# V32F20x_CM33 register map
File version: 1.0.3
CPU: CM33 r0p4, little endian, MPU, FPU, DSP, 3 interrupt priority bits, 8 SAU regions
Registers are 32-bit, read-write, reset 0x0 unless marked. A register's access mark holds for its fields unless they carry their own. Offsets are from the block's base; [hi:lo] are bit positions; {n}, {i} and the like mark numbered series.

## CRC — CRC Peripheral Interface
Base 0x20300000
Same registers: SEC_CRC 0x30300000
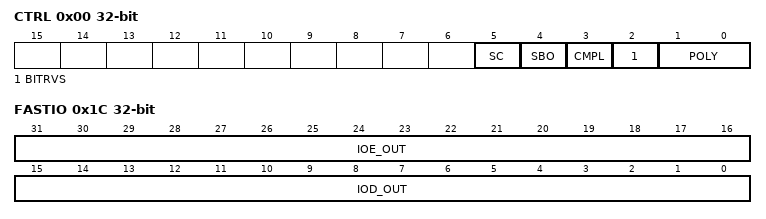
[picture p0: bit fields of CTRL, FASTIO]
0x00 CTRL — Control register.
  [5] SC — CRC sum complement
  [4] SBO — CRC sum bit order
  [3] CMPL — Data complement
  [2] BITRVS — Data bit order
  [1:0] POLY — CRC polynomial:
0x04 SEED wo reset 0xFFFF
  [31:0] SEED — A write access to this register will load CRC seed value to SUM register with select bit order and 1 s complement pre processes
0x08 SUM ro reset 0xFFFF
  [31:0] SUM — The most recent CRC sum can be read through this register with selected bit order and 1 s complement post processes
0x0C DATA wo
  [31:0] DATA — Data written to this register will be taken to perform CRC calculation with selected bit order and 1 s complement pre process
0x10 STATUS ro
  [0] BUSY — When assert to 1 it means the CRC Engine is busy on processing CRC command
0x1C FASTIO — Fast GPIO output data register.
  [31:16] IOE_OUT — The fast GPIOE output data.
  [15:0] IOD_OUT — The fast GPIOD output data.

## UART0 — UART0 Peripheral Interface
Base 0x40010000
Same registers: UART{n} {0x40010000+0x800*n} (n=1..13), UART14 0x41030000, UART15 0x41030800, UART16 0x41031000, UART17 0x41031800, UART18 0x41032000, UART19 0x41032800, SEC_UART{n} {0x50010000+0x800*n} (n=0..13)
0x00 RBR ro — Receive buffer register.
  [7:0] RBR — This register contains the data byte received on the serial input port sin in UART mode If in non FIFO mode the data in the RBR must be read before the next data arrives otherwise it will be overwritten resulting in an over run error
0x00 DLL (alternate view of RBR) — Divisor latch low register.
  [7:0] DLL — Divisor latch (low).
0x00 THR wo (alternate view of RBR) — Transmit holding register.
  [7:0] THR
0x04 DLH — Divisor latch high register.
  [7:0] DLH — Upper 8 bits of a 16 bit read write Divisor Latch register that contains the baud rate divisor for the UART
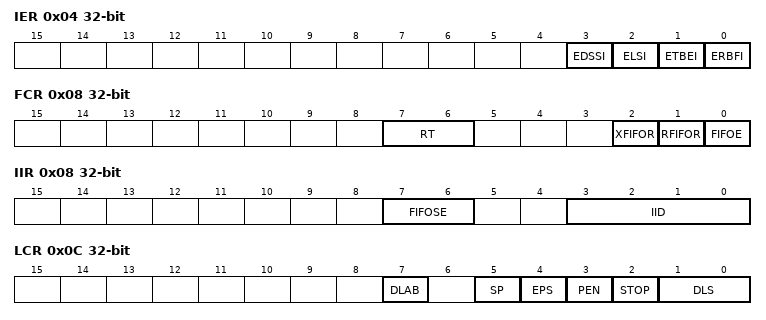
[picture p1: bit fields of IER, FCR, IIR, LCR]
0x04 IER (alternate view of DLH) — Interrupt enable register.
  [3] EDSSI — This is used to enable disable the generation of Modem Status Interrupt
  [2] ELSI — This is used to enable disable the generation of Receiver Line Status Interrupt
  [1] ETBEI — Enable Transmit Holding Register Empty Interrupt
  [0] ERBFI — Enable Received Data Available Interrupt
0x08 FCR wo — FIFO control register.
  [7:6] RT — This is used to select the trigger level in the receiver FIFO at which the Received Data Available Interrupt will be generated
  [2] XFIFOR — This resets the control portion of the transmit FIFO and treats the FIFO as empty
  [1] RFIFOR — This resets the control portion of the receive FIFO and treats the FIFO as empty
  [0] FIFOE — This bit enables disables the transmit and receive FIFOs
0x08 IIR (alternate view of FCR) — Interrupt identification register.
  [7:6] FIFOSE — This is used to indicate whether the FIFOs are enabled or disabled
  [3:0] IID — This indicates the highest priority pending interrupt which can be one of the following types specified in Values
0x0C LCR — Line control register.
  [7] DLAB — Divisor Latch Access Bit.
  [5] SP — Stick Parity.
  [4] EPS — Even Parity Select.
  [3] PEN — Parity Enable.
  [2] STOP — Number of stop bits.
  [1:0] DLS — Data Length Select.
0x10 MCR wo — Modem control register.
  [6] SIRE — This is used to enable/ disable the IrDA SIR Mode
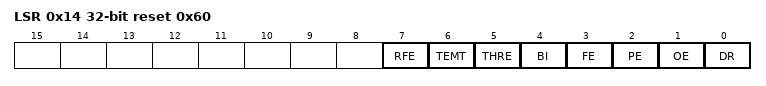
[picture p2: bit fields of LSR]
0x14 LSR ro reset 0x60 — Line status register.
  [7] RFE — Receiver FIFO Error bit.
  [6] TEMT — Transmitter Empty bit.
  [5] THRE — Transmit Holding Register Empty bit.
  [4] BI — Break Interrupt bit.
  [3] FE — Framing Error bit.
  [2] PE — Parity Error bit.
  [1] OE — Overrun error bit.
  [0] DR — Data Ready bit.
0x7C USR ro — UART status register.
  [0] BUSY — UART Busy.
0xC0 DLF — Divisor latch fraction register.
  [5:0] DLF — Fractional part of divisor.
